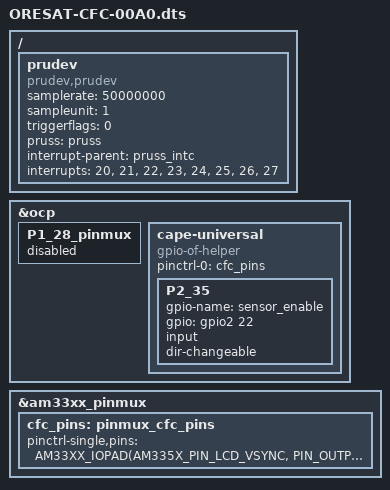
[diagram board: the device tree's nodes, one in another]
/* OreSat CFC overlay */

#include "am33xx.h"

/dts-v1/;
/plugin/;

/ {
  // disable the P1_28_pinmux as we define our own
  fragment@0 {
    target = <&ocp>;
    __overlay__ {
      P1_28_pinmux { status = "disabled"; };	/* gpio0_13.uart1_rtsn */
    };
  };

  fragment@1 {
    target-path="/";
    __overlay__ {
      /* Add default settings for the LA core */
      prudev {
        compatible = "prudev,prudev";
        samplerate = <50000000>;	/* All (100 / n) MHz sample rates, = 1,2,... */ // TODO remove
        sampleunit = <1>;		/* 0:16-bit samples, 1:8-bit samples */
        triggerflags = <0>; 		/* 0:one-shot, 1:continuous */

        pruss = <&pruss>;
        interrupt-parent = <&pruss_intc>;
        interrupts = <20>, <21>, <22>, <23>, <24>, <25>, <26>, <27>;
        interrupt-names = "20", "21", "22", "23", "24", "25", "26", "27";
      };
    };
  };

  // overlay to enable CFC GPIO
  fragment@2 {
    target = <&ocp>;
    __overlay__ {
      cape-universal {
        compatible = "gpio-of-helper";
        status = "okay";
        pinctrl-names = "default";
        pinctrl-0 = <&cfc_pins>; /* this must point to pinmux name below */

        /* must overlay P2_35 because it is used by the pocketbeagle
           and I could not find a way to delete a node */
        P2_35 {
          gpio-name = "sensor_enable";
          gpio = <&gpio2 22 0>;
          input; // TODO remove
          dir-changeable; // TODO remove
        };
      };
    };
  };

  // overlay the pinmux with the pin modes we need
  fragment@3 {
    target = <&am33xx_pinmux>;
    __overlay__ {
      cfc_pins: pinmux_cfc_pins {
            pinctrl-single,pins = <
              AM33XX_IOPAD(AM335X_PIN_LCD_VSYNC, PIN_OUTPUT_PULLDOWN | INPUT_EN | MUX_MODE7)
              >;
      };
    };
  };
};
